# STM32WB09 register map
File version: 1.0
CPU: CM0+ r0p0, little endian, MPU, no FPU, 2 interrupt priority bits
Registers are 32-bit, read-write, reset 0x0 unless marked. A register's access mark holds for its fields unless they carry their own. Offsets are from the block's base; [hi:lo] are bit positions; {n}, {i} and the like mark numbered series; 'fields as' and 'values as' point back to an identical list.

## TRNG
Base 0x48600000
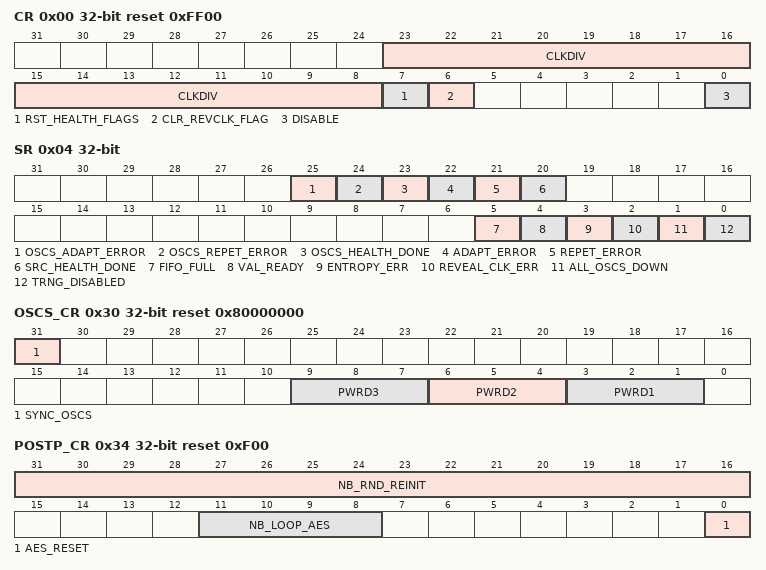
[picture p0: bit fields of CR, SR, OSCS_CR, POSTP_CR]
0x00 CR reset 0xFF00 — TRNG_CR register
  [23:8] CLKDIV — Sampling Clock Enable Divider. CLKDIV[15:0] control the sampling clock enable divider, dividing by a factor equal to CLKDIV[15:0] + 1, values being in the range of 1 to 65536.
  [7] RST_HEALTH_FLAGS — Reset Health error flags when writing a '1' without resetting the whole TRNG. When writing a 1, the value remains until it is seen by RNG core clock domain after resynchronization. Then it is automatically reset.
  [6] CLR_REVCLK_FLAG — Reset reveal clock error flags when writing a '1' without resetting the whole TRNG. When writing a 1, the value remains until it is seen by RNG core clock domain after resynchronization. Then it is automatically reset.
  [0] DISABLE — Disable Bit DISABLE can be used for reading or setting the state of the TRNG core. The value read is always the one available at the rng core clock domain. When changing the value, the change is effective when the value read is the same as the one written.
0x04 SR ro — TRNG_SR register
  [25] OSCS_ADAPT_ERROR — Logical OR of adaptive health test errors of individual oscillators composing the noise source.
  [24] OSCS_REPET_ERROR — Logical OR of repetition health test errors of individual oscillators composing the noise source.
  [23] OSCS_HEALTH_DONE — First run of source health tests of individual oscillators composing the noise source are completed.Reserved
  [22] ADAPT_ERROR — Noise source Adaptive 1024 health test error
  [21] REPET_ERROR — Noise source Repetition health test error
  [20] SRC_HEALTH_DONE — First run of noise source health test is completed
  [5] FIFO_FULL — Indicates whether random data FIFO is full.
  [4] VAL_READY — TRNG Value ready At least one 32-bit random value is available in the data FIFO. Note that application must ensure that a random is available in internal FIFO before starting a read otherwise a bus error will be generated.
  [3] ENTROPY_ERR — The error refers to a fault in the bit sequence detected by the Entropy Monitor. Failed test is given by REPET_ERROR, and ADAPT_ERROR, OSCS_REPET_ERROR and OSCS_ADAPT_ERROR status flags.
  [2] REVEAL_CLK_ERR — The internal clock for the RNG core is not revealed.
  [1] ALL_OSCS_DOWN — All oscillators of the random source noise have been powered down. This can cause the rising of OEC3 flag.
  [0] TRNG_DISABLED — TRNG is disabled.
0x08 VAL ro — TRNG_VAL register
  [31:0] RND_VAL — RND_VAL is a 32-bit Random Value. This is the output of the internal four-word FIFO. Note that application must ensure that a random is available in FIFO by ready VAL_READY flag before starting a read otherwise a null value will be returned.
0x30 OSCS_CR reset 0x80000000 — TRNG_OSCS_CR register
  [31] SYNC_OSCS — When set, selection of resynchronized output of oscillators.
  [9:7] PWRD3 — Power down of individual oscillators in triple-oscillator block number 3
  [6:4] PWRD2 — Power down of individual oscillators in triple-oscillator block number 2
  [3:1] PWRD1 — Power down of individual oscillators in triple-oscillator block number 1
0x34 POSTP_CR reset 0xF00 — TRNG_POSTP_CR register
  [31:16] NB_RND_REINIT — Number of 128-bit random words generated before AES automatically resets. This number is in the range of 1 to 65535 words. Value 0x0000 means that AES is never reinitialized.
  [11:8] NB_LOOP_AES — NB_LOOP_AES is the number of 128-bit words got from the noise source that have to be processed by AES for generating a single 128-bit random word. By default, this value is set to 2 (128 bits generated before an AES processing). 0 value means 16 loops. A new AES processing is started only when the previous one is completed.
  [0] AES_RESET — Reset AES post processing. When writing a 1, the AES post processing is reinitialized, resulting in a new key and new state generation before 128-bit random words generation. The '1' written is frozen until it is seen by RNG core clock domain after resynchronization. Then it is automatically reset. It also reruns analog source health tests.
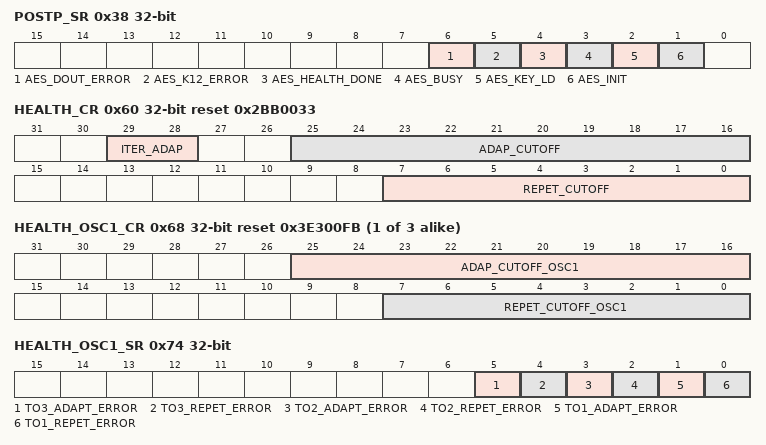
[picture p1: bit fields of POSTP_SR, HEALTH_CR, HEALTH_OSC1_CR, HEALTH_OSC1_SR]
0x38 POSTP_SR ro — TRNG_POSTP_SR register
  [6] AES_DOUT_ERROR — Health test error on AES-CMAC output generation
  [5] AES_K12_ERROR — Health test error on AES-CMAC sub-keys generation
  [4] AES_HEALTH_DONE — AES-CMAC health test is completed
  [3] AES_BUSY — AES core is busy, generating a random value.
  [2] AES_KEY_LD — AES random key has been generated and loaded in AES key register.
  [1] AES_INIT — AES Post processing has been fully initialized (key and state) and is ready for generating 128-bit random words.
0x40 DEFKEY0 reset 0xFFFFFFFF — TRNG_DEFKEY0 register
  [31:0] RNG_DEFKEY0 — Bits 31 to 0 of AES 128-bit Default Key.
0x44 DEFKEY1 reset 0xFFFFFFFF — TRNG_DEFKEY1 register
  [31:0] RNG_DEFKEY1 — Bits 63 to 31 of AES 128-bit Default Key.
0x48 DEFKEY2 reset 0xFFFFFFFF — TRNG_DEFKEY2 register
  [31:0] RNG_DEFKEY2 — Bits 95 to 64 of AES 128-bit Default Key.
0x4C DEFKEY3 reset 0xFFFFFFFF — TRNG_DEFKEY3 register
  [31:0] RNG_DEFKEY3 — Bits 127 to 96 of AES 128-bit Default Key.
0x60 HEALTH_CR reset 0x2BB0033 — TRNG_HEALTH_CR register
  [29:28] ITER_ADAP — Number of iterations minus 1 of Adaptive test during initialization phase. Default value is set to 0 i.e. 1 iteration.
  [25:16] ADAP_CUTOFF — Cutoff value of Adaptive Test. The default value is set to 699. Caution: To be handled with care as any change can lead to misbehavior of TRNG.
  [7:0] REPET_CUTOFF — Cutoff value of Repetition Test. The default value is set to 51. Caution: To be handled with care as any change can lead to misbehavior of TRNG.
{0x64+4i} HEALTH_OSC{i}_CR reset 0x3E300FB (i=1..3) — TRNG_HEALTH_OSC{i}_CR register
  [25:16] ADAP_CUTOFF_OSC{i} — Cutoff value of Adaptive Test. The default value is set to 699. Caution: To be handled with care as any change can lead to misbehavior of TRNG.
  [7:0] REPET_CUTOFF_OSC{i} — Cutoff value of Repetition Test. The default value is set to 51. Caution: To be handled with care as any change can lead to misbehavior of TRNG.
0x74 HEALTH_OSC1_SR ro — TRNG_HEALTH_OSC1_SR register
  [5] TO3_ADAPT_ERROR — Adaptive error flag of first oscillator of third triple-oscillator cell.
  [4] TO3_REPET_ERROR — Repetition error flag of first oscillator of third triple-oscillator cell.
  [3] TO2_ADAPT_ERROR — Adaptive error flag of first oscillator of second triple-oscillator cell.
  [2] TO2_REPET_ERROR — Repetition error flag of first oscillator of second triple-oscillator cell.
  [1] TO1_ADAPT_ERROR — Adaptive error flag of first oscillator of first triple-oscillator cell.
  [0] TO1_REPET_ERROR — Repetition error flag of first oscillator of first triple-oscillator cell.
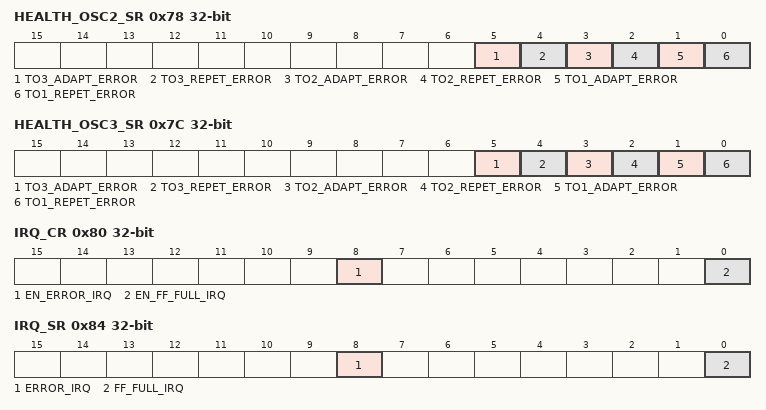
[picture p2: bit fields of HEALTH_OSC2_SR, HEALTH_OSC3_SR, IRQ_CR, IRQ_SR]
0x78 HEALTH_OSC2_SR ro — TRNG_HEALTH_OSC2_SR register
  fields as HEALTH_OSC1_SR
0x7C HEALTH_OSC3_SR ro — TRNG_HEALTH_OSC3_SR register
  [5] TO3_ADAPT_ERROR — Adaptive error flag of first oscillator of third triple-oscillator cell.
  [4] TO3_REPET_ERROR — Repetition error flag of first oscillator of third triple-oscillator cell.
  [3] TO2_ADAPT_ERROR — Adaptive error flag of first oscillator of second triple-oscillator cell.
  [2] TO2_REPET_ERROR — Repetition error flag of first oscillator of second triple-oscillator cell.
  [1] TO1_ADAPT_ERROR — Adaptive error flag of first oscillator of first triple-oscillator cell.
  [0] TO1_REPET_ERROR — Repetition error flag of third oscillator of first triple-oscillator cell.
0x80 IRQ_CR — TRNG_IRQ_CR register
  [8] EN_ERROR_IRQ — Enable the interrupt when an error is reported by the health tests.
  [0] EN_FF_FULL_IRQ — Enable the interrupt when the output fifo is full of new random.
0x84 IRQ_SR ro — TRNG_IRQ_SR register
  [8] ERROR_IRQ — Set to 1 when an error is reported by the health tests. Flag is cleared by writing a 1.
  [0] FF_FULL_IRQ — Set to 1 when the output fifo is full of new random. Flag is cleared by writing a 1.
